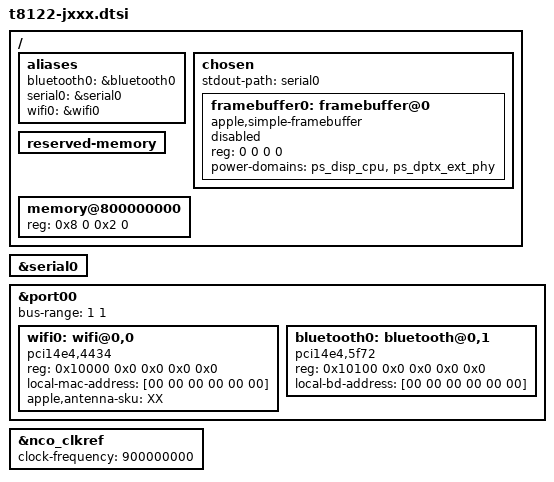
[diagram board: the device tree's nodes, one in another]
// SPDX-License-Identifier: GPL-2.0+ OR MIT
/*
 * Apple M3 MacBook Air/Pro and iMac (M3, 2023/2024)
 *
 * This file contains parts common to all Apple M3 devices using the t8122.
 *
 * target-type: J433, J434, J504, J613, J615
 *
 * Copyright The Asahi Linux Contributors
 */

/ {
	aliases {
		bluetooth0 = &bluetooth0;
		serial0 = &serial0;
		wifi0 = &wifi0;
	};

	chosen {
		ranges;
		#address-cells = <2>;
		#size-cells = <2>;

		stdout-path = "serial0";

		framebuffer0: framebuffer@0 {
			compatible = "apple,simple-framebuffer",
				     "simple-framebuffer";
			reg = <0 0 0 0>; /* To be filled by loader */
			power-domains = <&ps_disp_cpu>, <&ps_dptx_ext_phy>;
			/* Format properties will be added by loader */

			status = "disabled";
		};
	};

	reserved-memory {
		ranges;
		#address-cells = <2>;
		#size-cells = <2>;
		/* To be filled by loader */
	};

	memory@800000000 {
		device_type = "memory";
		reg = <0x8 0 0x2 0>; /* To be filled by loader */
	};
};

&serial0 {
	status = "okay";
};

/*
 * Force the bus number assignments so that we can declare some of the
 * on-board devices and properties that are populated by the bootloader
 * (such as MAC addresses).
 */
&port00 {
	bus-range = <1 1>;

	wifi0: wifi@0,0 {
		compatible = "pci14e4,4434";
		reg = <0x10000 0x0 0x0 0x0 0x0>;
		/* To be filled by the loader */
		local-mac-address = [00 00 00 00 00 00];
		apple,antenna-sku = "XX";
	};

	bluetooth0: bluetooth@0,1 {
		compatible = "pci14e4,5f72";
		reg = <0x10100 0x0 0x0 0x0 0x0>;
		/* To be filled by the loader */
		local-bd-address = [00 00 00 00 00 00];
	};
};

&nco_clkref {
	clock-frequency = <900000000>;
};

#include "hwmon-common.dtsi"

#include "spi1-nvram.dtsi"
